VERSION ""

NS_ :

BS_: 500

BU_: Vector__XXX

BO_ 133 MSG_085: 5 Vector__XXX
 SG_ Steering_Angle : 0|16@1- (-0.1,0) [-540|540] "��" Vector__XXX

BO_ 162 MSG_0A2: 7 Vector__XXX
 SG_ Wheel_Speed_1_kph : 0|14@1+ (0.067942,0) [0|322] "km/h" Vector__XXX
 SG_ Wheel_Speed_1_mph : 0|14@1+ (0.0422,0) [0|200] "mph" Vector__XXX
 SG_ Wheel_Speed_2_kph : 14|14@1+ (0.067942,0) [0|322] "km/h" Vector__XXX
 SG_ Wheel_Speed_2_mph : 14|14@1+ (0.0422,0) [0|200] "mph" Vector__XXX

BO_ 164 MSG_0A4: 8 Vector__XXX
 SG_ Wheel_Speed_3_kph : 0|14@1+ (0.067942,0) [0|26376.63] "km/h" Vector__XXX
 SG_ Wheel_Speed_3_mph : 0|14@1+ (0.0422,0) [0|16383] "mph" Vector__XXX
 SG_ Wheel_Speed_4_kph : 14|14@1+ (0.067942,0) [0|26376.63] "km/h" Vector__XXX
 SG_ Wheel_Speed_4_mph : 14|14@1+ (0.0422,0) [0|16383] "mph" Vector__XXX

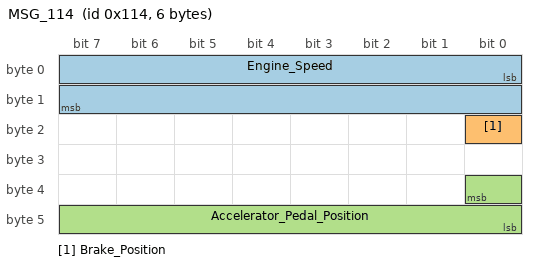
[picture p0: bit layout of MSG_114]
BO_ 276 MSG_114: 6 Vector__XXX
 SG_ Engine_Speed : 0|16@1+ (0.25,0) [0|10000] "rpm" Vector__XXX
 SG_ Brake_Position : 16|1@0+ (1,0) [0|0] "on/off" Vector__XXX
 SG_ Accelerator_Pedal_Position : 32|9@0+ (0.4,0) [0|100] "%" Vector__XXX

BO_ 1024 MSG_400: 7 Vector__XXX
 SG_ Coolant_Temperature : 16|8@0- (0.1,0) [0|0] "��C" Vector__XXX
